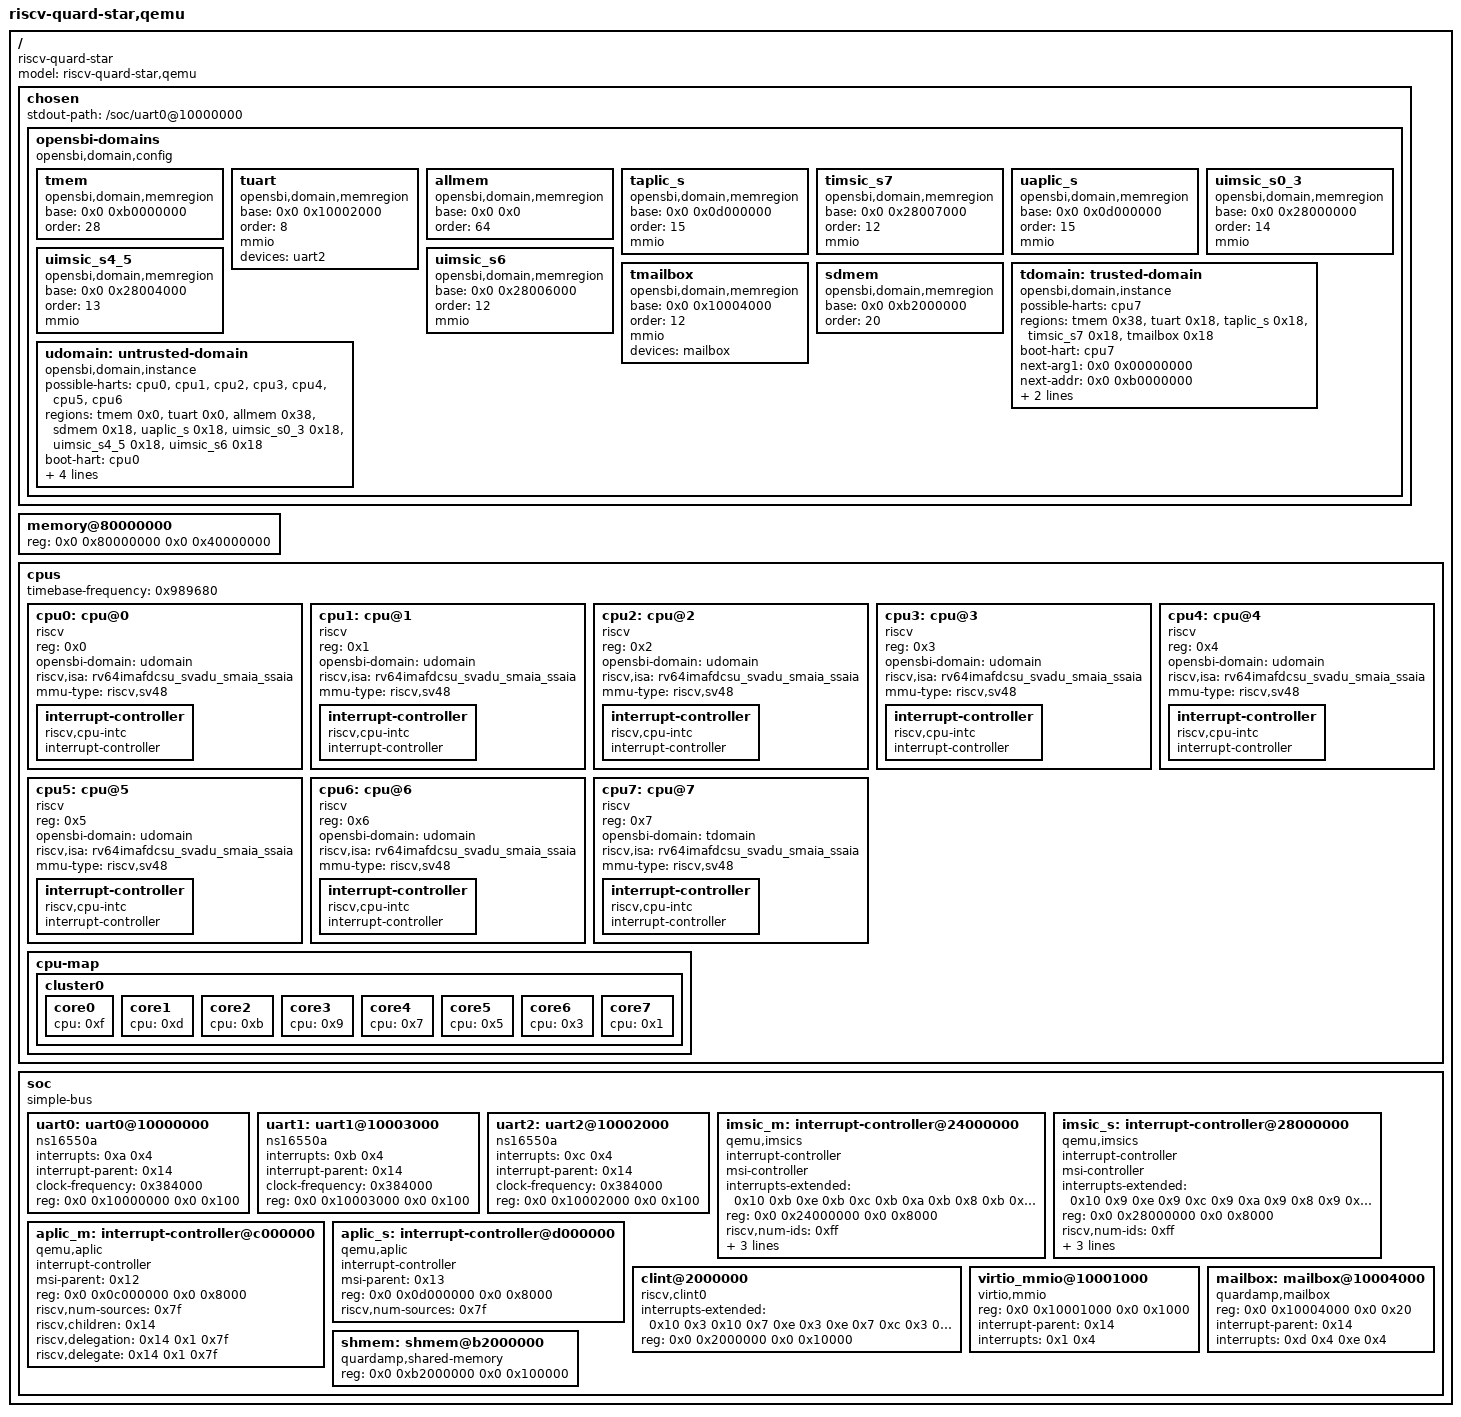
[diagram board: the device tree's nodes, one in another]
/dts-v1/;

/* 定义根节点 */
/ {
    #address-cells = <0x2>; /* 决定了 reg 属性中“地址”使用几个 32 位的单元 */
    #size-cells = <0x2>; /* reg 属性中“大小”使用几个 32 位的单元 */
    compatible = "riscv-quard-star";
    model = "riscv-quard-star,qemu";

    /* 定义chosen子节点，用于传递输入参数 */   
	chosen {
		stdout-path = "/soc/uart0@10000000";  /* 定义系统标准输出stdout使用节点/soc/uart0@10000000 */

		opensbi-domains {
			compatible = "opensbi,domain,config"; /* 节点名称 */

			tmem: tmem {   /* 定义内存节点 */
				compatible = "opensbi,domain,memregion";  /* 节点名称 */
				base = <0x0 0xb0000000>; /* 起始地址注意64位地址哦 */
				order = <28>; /* 内存大小即size=2^28 */
			};

			tuart: tuart {  /* 定义mmio节点 */
				compatible = "opensbi,domain,memregion";  /* 节点名称 */
				base = <0x0 0x10002000>; /* 起始地址 */
				order = <8>; /* size=2^8 */
				mmio;  /* mmio属性 */
				devices = <&uart2>; /* 关联到设备节点上 */
			};

			allmem: allmem { /* 定义内存节点，这个节点保护所有地址 */
				compatible = "opensbi,domain,memregion";
				base = <0x0 0x0>;
				order = <64>;
			};

			taplic_s: taplic_s {
				compatible = "opensbi,domain,memregion";
				base = <0x0 0x0d000000>;
				order = <15>; /* 32 KiB，覆盖 S-mode APLIC */
				mmio;
			};

			timsic_s7: timsic_s7 {
				compatible = "opensbi,domain,memregion";
				base = <0x0 0x28007000>;
				order = <12>; /* hart7 的 S-mode IMSIC page */
				mmio;
			};

			uaplic_s: uaplic_s {
				compatible = "opensbi,domain,memregion";
				base = <0x0 0x0d000000>;
				order = <15>; /* 32 KiB，覆盖 S-mode APLIC */
				mmio;
			};

			uimsic_s0_3: uimsic_s0_3 {
				compatible = "opensbi,domain,memregion";
				base = <0x0 0x28000000>;
				order = <14>; /* hart0~3 的 S-mode IMSIC pages */
				mmio;
			};

			uimsic_s4_5: uimsic_s4_5 {
				compatible = "opensbi,domain,memregion";
				base = <0x0 0x28004000>;
				order = <13>; /* hart4~5 的 S-mode IMSIC pages */
				mmio;
			};

			uimsic_s6: uimsic_s6 {
				compatible = "opensbi,domain,memregion";
				base = <0x0 0x28006000>;
				order = <12>; /* hart6 的 S-mode IMSIC page */
				mmio;
			};

			/*
			 * AMP mailbox MMIO 区域。
			 * base 0x10004000 与 QEMU quard_star.c 的 QUARD_STAR_MAILBOX 一致，
			 * order=12 即 4 KiB（base 需按 2^order 对齐）。
			 * trusted-domain（FreeRTOS/hart7）需显式声明该区域才能访问；
			 * untrusted-domain 已由 allmem 覆盖，无需额外声明。
			 */
			tmailbox: tmailbox {
				compatible = "opensbi,domain,memregion";
				base = <0x0 0x10004000>;
				order = <12>;
				mmio;
				devices = <&mailbox>;
			};

			sdmem: sdmem {
				compatible = "opensbi,domain,memregion";
				base = <0x0 0xb2000000>;
				order = <20>; /* 1 MiB */
			};


			tdomain: trusted-domain { /* 定义domain节点 */
				compatible = "opensbi,domain,instance";  /* 节点名称 */
				possible-harts = <&cpu7>; /* domain中允许使用的cpu core */
				/* 给某个 domain 配它能访问哪些内存/MMIO 区域，以及访问权限。 */
				regions = <&tmem 0x38>, <&tuart 0x18>, <&taplic_s 0x18>, <&timsic_s7 0x18>, <&tmailbox 0x18>;/* OpenSBI权限位: bit[3:5]为S/U读写执行权限 */
				boot-hart = <&cpu7>; /* domain中用于boot的core */
				next-arg1 = <0x0 0x00000000>; /* 下级程序的参数 */
				next-addr = <0x0 0xb0000000>; /* 下级程序的起始地址 */
				next-mode = <0x1>; /* 下级程序的允许模式 0为U模式，1为S模式 */
				system-reset-allowed; /* 允许复位 */
			};

			udomain: untrusted-domain {
				compatible = "opensbi,domain,instance";
				possible-harts = <&cpu0 &cpu1 &cpu2 &cpu3 &cpu4 &cpu5 &cpu6>;
				regions = <&tmem 0x0>, <&tuart 0x0>, <&allmem 0x38>, <&sdmem 0x18>, <&uaplic_s 0x18>, <&uimsic_s0_3 0x18>, <&uimsic_s4_5 0x18>, <&uimsic_s6 0x18>;
				boot-hart = <&cpu0>;
				next-arg1 = <0x0 0x82200000>;
				next-addr = <0x0 0x82000000>;
				next-mode = <0x1>;
				system-reset-allowed;
			};
		};
	};

    /* 定义memory子节点，用于定义系统主内存 */   
	memory@80000000 {
		device_type = "memory";    /* 设备类型 */
		reg = <0x0 0x80000000 0x0 0x40000000>;  /* 地址和大小定义，注意是64位的 */
	};

    /* 定义cpus子节点，用于定义系统核心信息 */ 
    cpus {
        #address-cells = <0x1>; /* 节点中的reg的地址宽度为32位 */
		#size-cells = <0x0>; /* 节点中的reg没有大小*/

        /* CPU 主频（如 1.2 GHz）是指 CPU 核心执行指令的速度，通常远高于定时器基准频率。
         * timebase-frequency 是一个独立且相对较低的固定频率，主要用于操作系统进行时间管理，
         * 比如计算时间片、系统 jiffies 等
         */
		timebase-frequency = <0x989680>; /*自定义的属性 即 10 MHz */

        cpu0: cpu@0 {             /* 定义cpu0子节点 */   
			phandle = <0xf>;      /* 其他具体的属性在驱动代码内针对使用 */
			device_type = "cpu";
            /* reg 属性是设备树中用于定义设备地址空间的标准属性。
             * 对于 CPU 节点，它的值（<0x0>）表示该 CPU 核心的硬件 ID。 
             */
			reg = <0x0>;
			status = "okay";      /* status属性用来表示启用该设备 */   
			compatible = "riscv";
			opensbi-domain = <&udomain>;
			riscv,isa = "rv64imafdcsu_svadu_smaia_ssaia";
			mmu-type = "riscv,sv48";

			interrupt-controller { /* 定义中断控制器子节点 */   
				#interrupt-cells = <0x1>;
				interrupt-controller;
				compatible = "riscv,cpu-intc";
				phandle = <0x10>; 
                /* 为该节点分配一个唯一的数字句柄，
                 * 以便其他节点（如 plic 或 clint）在 interrupts-extended 属性中引用它。 
                 */
			};
		};

        cpu1: cpu@1 {             /* 定义cpu1子节点 */   
			phandle = <0xd>;      /* 其他具体的属性在驱动代码内针对使用 */
			device_type = "cpu";
            /* reg 属性是设备树中用于定义设备地址空间的标准属性。
             * 对于 CPU 节点，它的值（<0x0>）表示该 CPU 核心的硬件 ID。 
             */
			reg = <0x1>;
			status = "okay";      /* status属性用来表示启用该设备 */   
			compatible = "riscv";
			opensbi-domain = <&udomain>;
			riscv,isa = "rv64imafdcsu_svadu_smaia_ssaia";
			mmu-type = "riscv,sv48";

			interrupt-controller { /* 定义中断控制器子节点 */   
				#interrupt-cells = <0x1>;
				interrupt-controller;
				compatible = "riscv,cpu-intc";
				phandle = <0xe>; 
			};
		};

        cpu2: cpu@2 {             
			phandle = <0xb>;      
			device_type = "cpu";
			reg = <0x2>;
			status = "okay";      
			compatible = "riscv";
			opensbi-domain = <&udomain>;
			riscv,isa = "rv64imafdcsu_svadu_smaia_ssaia";
			mmu-type = "riscv,sv48";

			interrupt-controller { 
				#interrupt-cells = <0x1>;
				interrupt-controller;
				compatible = "riscv,cpu-intc";
				phandle = <0xc>; 
			};
		};

        cpu3: cpu@3 {
			phandle = <0x9>;
			device_type = "cpu";
			reg = <0x3>;
			status = "okay";
			compatible = "riscv";
			opensbi-domain = <&udomain>;
			riscv,isa = "rv64imafdcsu_svadu_smaia_ssaia";
			mmu-type = "riscv,sv48";

			interrupt-controller {
				#interrupt-cells = <0x1>;
				interrupt-controller;
				compatible = "riscv,cpu-intc";
				phandle = <0xa>;
			};
		};

        cpu4: cpu@4 {
			phandle = <0x7>;
			device_type = "cpu";
			reg = <0x4>;
			status = "okay";
			compatible = "riscv";
			opensbi-domain = <&udomain>;
			riscv,isa = "rv64imafdcsu_svadu_smaia_ssaia";
			mmu-type = "riscv,sv48";

			interrupt-controller {
				#interrupt-cells = <0x1>;
				interrupt-controller;
				compatible = "riscv,cpu-intc";
				phandle = <0x8>;
			};
		};

        cpu5: cpu@5 {
			phandle = <0x5>;
			device_type = "cpu";
			reg = <0x5>;
			status = "okay";
			compatible = "riscv";
			opensbi-domain = <&udomain>;
			riscv,isa = "rv64imafdcsu_svadu_smaia_ssaia";
			mmu-type = "riscv,sv48";

			interrupt-controller {
				#interrupt-cells = <0x1>;
				interrupt-controller;
				compatible = "riscv,cpu-intc";
				phandle = <0x6>;
			};
		};

        cpu6: cpu@6 {
			phandle = <0x3>;
			device_type = "cpu";
			reg = <0x6>;
			status = "okay";
			compatible = "riscv";
			opensbi-domain = <&udomain>;
			riscv,isa = "rv64imafdcsu_svadu_smaia_ssaia";
			mmu-type = "riscv,sv48";

			interrupt-controller {
				#interrupt-cells = <0x1>;
				interrupt-controller;
				compatible = "riscv,cpu-intc";
				phandle = <0x4>;
			};
		};

		cpu7: cpu@7 {
			phandle = <0x1>;
			device_type = "cpu";
			reg = <0x7>;
			status = "okay";
			compatible = "riscv";
			opensbi-domain = <&tdomain>;
			riscv,isa = "rv64imafdcsu_svadu_smaia_ssaia";
			mmu-type = "riscv,sv48";

			interrupt-controller {
				#interrupt-cells = <0x1>;
				interrupt-controller;
				compatible = "riscv,cpu-intc";
				phandle = <0x2>;
			};
		};

        /* 用于描述 CPU 核心的物理拓扑结构的标准方式。
        * 它明确地将 8 个 CPU 核心组织成一个单簇（Cluster0），
        * 并定义了每个核心在簇内的编号 
        */
        cpu-map {

			cluster0 {

				core0 {
					cpu = <0xf>;
				};

				core1 {
					cpu = <0xd>;
				};

				core2 {
					cpu = <0xb>;
				};

				core3 {
					cpu = <0x9>;
				};

				core4 {
					cpu = <0x7>;
				};

				core5 {
					cpu = <0x5>;
				};

				core6 {
					cpu = <0x3>;
				};

				core7 {
					cpu = <0x1>;
				};
			};
		};
    };

    /* 定义soc子节点，用于定义系统内外设信息 */ 
    soc {
        #address-cells = <0x2>; /* 节点中的reg的地址宽度为64位 */
		#size-cells = <0x2>;    /* 节点中的reg的大小宽度为64位 */
		compatible = "simple-bus";
		ranges;  /* 子节点地址空间和父地址空间的映射计算方式，这里为空是直接映射的 */

        /* uart信息和中断控制器信息，
         * soc目前只有这两种外设
         * 用于设备驱动的具体的设备属性
         * 需要结合驱动源码确认属性如何使用 
        */
	        uart0: uart0@10000000 {
			interrupts = <0xa 0x4>; /* APLIC source 10, level-high */
			interrupt-parent = <0x14>;
			clock-frequency = <0x384000>;
			reg = <0x0 0x10000000 0x0 0x100>;
			compatible = "ns16550a";
		};

	        uart1: uart1@10003000 {
			interrupts = <0xb 0x4>;
			interrupt-parent = <0x14>;
			clock-frequency = <0x384000>;
			reg = <0x0 0x10003000 0x0 0x100>;
			compatible = "ns16550a";
		};

	        uart2: uart2@10002000 {
			interrupts = <0xc 0x4>;
			interrupt-parent = <0x14>;
			clock-frequency = <0x384000>;
			reg = <0x0 0x10002000 0x0 0x100>;
			compatible = "ns16550a";
		};

        imsic_m: interrupt-controller@24000000 {
			compatible = "qemu,imsics", "riscv,imsics";
			#interrupt-cells = <0x0>;
			interrupt-controller;
			msi-controller;
			interrupts-extended = <0x10 0xb 0xe 0xb 0xc 0xb 0xa 0xb 0x8 0xb 0x6 0xb 0x4 0xb 0x2 0xb>;
			reg = <0x0 0x24000000 0x0 0x8000>;
			riscv,num-ids = <0xff>;
			riscv,hart-index-bits = <0x3>;
			riscv,group-index-bits = <0x0>;
			riscv,group-index-shift = <0x18>;
			phandle = <0x12>;
		};

        imsic_s: interrupt-controller@28000000 {
			compatible = "qemu,imsics", "riscv,imsics";
			#interrupt-cells = <0x0>;
			interrupt-controller;
			msi-controller;
			interrupts-extended = <0x10 0x9 0xe 0x9 0xc 0x9 0xa 0x9 0x8 0x9 0x6 0x9 0x4 0x9 0x2 0x9>;
			reg = <0x0 0x28000000 0x0 0x8000>;
			riscv,num-ids = <0xff>;
			riscv,hart-index-bits = <0x3>;
			riscv,group-index-bits = <0x0>;
			riscv,group-index-shift = <0x18>;
			phandle = <0x13>;
		};

        aplic_m: interrupt-controller@c000000 {
			compatible = "qemu,aplic", "riscv,aplic";
			#address-cells = <0x0>;
			#interrupt-cells = <0x2>;
			interrupt-controller;
			msi-parent = <0x12>;
			reg = <0x0 0x0c000000 0x0 0x8000>;
			riscv,num-sources = <0x7f>;
			riscv,children = <0x14>;
			riscv,delegation = <0x14 0x1 0x7f>;
			riscv,delegate = <0x14 0x1 0x7f>;
			phandle = <0x11>;
		};

        aplic_s: interrupt-controller@d000000 {
			compatible = "qemu,aplic", "riscv,aplic";
			#address-cells = <0x0>;
			#interrupt-cells = <0x2>;
			interrupt-controller;
			msi-parent = <0x13>;
			reg = <0x0 0x0d000000 0x0 0x8000>;
			riscv,num-sources = <0x7f>;
			phandle = <0x14>;
		};

        /* CLINT 负责管理每个 CPU 核心私有的、内部产生的中断，主要包括软件中断（IPI）和定时器中断。 */
        clint@2000000 {
            /* 0x10 0x7 同样连接 CPU0，0x7 是定时器中断号 */
            /* 0x10 0x3 同样连接 CPU0，0x3 是软件中断号 */
			interrupts-extended = <0x10 0x3 0x10 0x7 0xe 0x3 0xe 0x7 0xc 0x3 0xc 0x7 0xa 0x3 0xa 0x7 0x8 0x3 0x8 0x7 0x6 0x3 0x6 0x7 0x4 0x3 0x4 0x7 0x2 0x3 0x2 0x7>;
			reg = <0x0 0x2000000 0x0 0x10000>;
			compatible = "riscv,clint0";
		};

		virtio_mmio@10001000 {
			compatible = "virtio,mmio";
			reg = <0x0 0x10001000 0x0 0x1000>;
			interrupt-parent = <0x14>;
			interrupts = <0x1 0x4>; /* APLIC source 1, level-high */
		};

		/*
		 * AMP mailbox 设备节点（quardamp-mailbox）。
		 * reg 与 QEMU 中 QUARD_STAR_MAILBOX 基址和 MemoryRegion 大小一致；
		 * OpenSBI domain memregion 单独按 4 KiB 对齐授权。
		 * interrupts 含两个 PLIC 中断源（#interrupt-cells=1，故为两个独立 spec）：
		 *   0xd (13) = MAILBOX_TO_RTOS_IRQ，xv6 写 mailbox 后通知 FreeRTOS
		 *   0xe (14) = MAILBOX_TO_XV6_IRQ， FreeRTOS 写 mailbox 后通知 xv6
		 * guest 驱动按索引区分方向。
		 */
		mailbox: mailbox@10004000 {
			compatible = "quardamp,mailbox";
			reg = <0x0 0x10004000 0x0 0x20>;
			interrupt-parent = <0x14>;
			interrupts = <0xd 0x4 0xe 0x4>;
		};

		shmem: shmem@b2000000 {
			compatible = "quardamp,shared-memory";
			reg = <0x0 0xb2000000 0x0 0x100000>;
		};

    };
};
